AUTOSAR XML (schema 4-0-3)
standard types defined: Boolean, UInt32
package /AUTOSAR_Platform/DataConstrs
  range DC_Boolean: raw 0..1
package /PATAC/Facility/DataTypes/Implementation
  compu method COMPU_Boolean: 0=FALSE, 1=TRUE
  unit NoUnit: factor-si-to-unit=1, offset-si-to-unit=0
package /PATAC/MSM/ComponentTypes
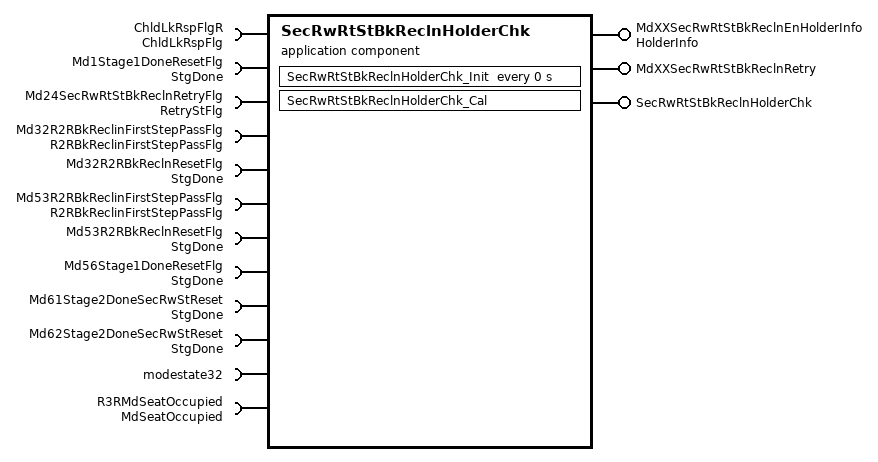
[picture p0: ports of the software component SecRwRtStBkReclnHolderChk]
  application sw component type SecRwRtStBkReclnHolderChk
    provide port MdXXSecRwRtStBkReclnEnHolderInfo: nonqueued-sender-com-spec{data-element=HolderInfo/Val, init-value=0}, provided-interface=HolderInfo
    provide port MdXXSecRwRtStBkReclnRetry: nonqueued-sender-com-spec{data-element=MdXXSecRwRtStBkReclnRetry/Val, init-value=0}, provided-interface=MdXXSecRwRtStBkReclnRetry
    provide port SecRwRtStBkReclnHolderChk: server-com-spec{operation=Cal, queue-length=1}, provided-interface=SecRwRtStBkReclnHolderChk
    12 x require port:
      ChldLkRspFlgR: nonqueued-receiver-com-spec{data-element=ChldLkRspFlg/Val, filter=data-filter-type=ALWAYS, init-value=0}, required-interface=ChldLkRspFlg
      Md1Stage1DoneResetFlg: nonqueued-receiver-com-spec{data-element=StgDone/Val, filter=data-filter-type=ALWAYS, init-value=0}, required-interface=StgDone
      Md24SecRwRtStBkReclnRetryFlg: nonqueued-receiver-com-spec{data-element=RetryStFlg/Val, filter=data-filter-type=ALWAYS, init-value=0}, required-interface=RetryStFlg
      Md32R2RBkReclinFirstStepPassFlg: nonqueued-receiver-com-spec{data-element=R2RBkReclinFirstStepPassFlg/Val, filter=data-filter-type=ALWAYS, init-value=0}, required-interface=R2RBkReclinFirstStepPassFlg
      Md32R2RBkReclnResetFlg: nonqueued-receiver-com-spec{data-element=StgDone/Val, filter=data-filter-type=ALWAYS, init-value=0}, required-interface=StgDone
      Md53R2RBkReclinFirstStepPassFlg: nonqueued-receiver-com-spec{data-element=R2RBkReclinFirstStepPassFlg/Val, filter=data-filter-type=ALWAYS, init-value=0}, required-interface=R2RBkReclinFirstStepPassFlg
      Md53R2RBkReclnResetFlg: nonqueued-receiver-com-spec{data-element=StgDone/Val, filter=data-filter-type=ALWAYS, init-value=0}, required-interface=StgDone
      Md56Stage1DoneResetFlg: nonqueued-receiver-com-spec{data-element=StgDone/Val, filter=data-filter-type=ALWAYS, init-value=0}, required-interface=StgDone
      Md61Stage2DoneSecRwStReset: nonqueued-receiver-com-spec{data-element=StgDone/Val, filter=data-filter-type=ALWAYS, init-value=0}, required-interface=StgDone
      Md62Stage2DoneSecRwStReset: nonqueued-receiver-com-spec{data-element=StgDone/Val, filter=data-filter-type=ALWAYS, init-value=0}, required-interface=StgDone
      modestate32: nonqueued-receiver-com-spec{data-element=modestate32/Val, filter=data-filter-type=ALWAYS, init-value=0}, required-interface=modestate32
      R3RMdSeatOccupied: nonqueued-receiver-com-spec{data-element=MdSeatOccupied/Val, filter=data-filter-type=ALWAYS, init-value=0}, required-interface=MdSeatOccupied
    behavior SecRwRtStBkReclnHolderChk_InternalBehavior
      operation invoked event OIT_SecRwRtStBkReclnHolderChk_Cal_SecRwRtStBkReclnHolderChk_Cal: start-on-event=SecRwRtStBkReclnHolderChk_Cal, operation=SecRwRtStBkReclnHolderChk.Cal
      timing event SecRwRtStBkReclnHolderChk_InitEvent: start-on-event=SecRwRtStBkReclnHolderChk_Init, period=0
      runnable SecRwRtStBkReclnHolderChk_Cal
        data-receive-point-by-arguments:
          12 x access:
            REC_ChldLkRspFlgR_Val: accessed-variable=ChldLkRspFlgR.Val
            REC_Md1Stage1DoneResetFlg_Val: accessed-variable=Md1Stage1DoneResetFlg.Val
            REC_Md24SecRwRtStBkReclnRetryFlg_Val: accessed-variable=Md24SecRwRtStBkReclnRetryFlg.Val
            REC_Md32R2RBkReclinFirstStepPassFlg_Val: accessed-variable=Md32R2RBkReclinFirstStepPassFlg.Val
            REC_Md32R2RBkReclnResetFlg_Val: accessed-variable=Md32R2RBkReclnResetFlg.Val
            REC_Md53R2RBkReclinFirstStepPassFlg_Val: accessed-variable=Md53R2RBkReclinFirstStepPassFlg.Val
            REC_Md53R2RBkReclnResetFlg_Val: accessed-variable=Md53R2RBkReclnResetFlg.Val
            REC_Md56Stage1DoneResetFlg_Val: accessed-variable=Md56Stage1DoneResetFlg.Val
            REC_Md61Stage2DoneSecRwStReset_Val: accessed-variable=Md61Stage2DoneSecRwStReset.Val
            REC_Md62Stage2DoneSecRwStReset_Val: accessed-variable=Md62Stage2DoneSecRwStReset.Val
            REC_modestate32_Val: accessed-variable=modestate32.Val
            REC_R3RMdSeatOccupied_Val: accessed-variable=R3RMdSeatOccupied.Val
        data-send-points:
          access SEND_MdXXSecRwRtStBkReclnEnHolderInfo_Val: accessed-variable=MdXXSecRwRtStBkReclnEnHolderInfo.Val
          access SEND_MdXXSecRwRtStBkReclnRetry_Val: accessed-variable=MdXXSecRwRtStBkReclnRetry.Val
      runnable SecRwRtStBkReclnHolderChk_Init
  swc implementation SecRwRtStBkReclnHolderChk_Implementation: behavior=SecRwRtStBkReclnHolderChk_InternalBehavior
    code-descriptors:
      code Default: artifact-descriptors=autosar-engineering-object={short-label=Default, category=SWSRC}
package /PATAC/MSM/ModeAdjust/PortInterface
  client server interface SecRwRtStBkReclnHolderChk
    operation Cal
  8 x sender receiver interface:
    ChldLkRspFlg: invalidation-policy{data-element=ChldLkRspFlg/Val, handle-invalid=DONT-INVALIDATE}
      data Val: type=Boolean
    HolderInfo: invalidation-policy{data-element=HolderInfo/Val, handle-invalid=DONT-INVALIDATE}
      data Val: type=UInt32
    MdSeatOccupied: invalidation-policy{data-element=MdSeatOccupied/Val, handle-invalid=DONT-INVALIDATE}
      data Val: type=Boolean
    MdXXSecRwRtStBkReclnRetry: invalidation-policy{data-element=MdXXSecRwRtStBkReclnRetry/Val, handle-invalid=DONT-INVALIDATE}
      data Val: type=UInt32
    modestate32: invalidation-policy{data-element=modestate32/Val, handle-invalid=DONT-INVALIDATE}
      data Val: type=UInt32
    R2RBkReclinFirstStepPassFlg: invalidation-policy{data-element=R2RBkReclinFirstStepPassFlg/Val, handle-invalid=DONT-INVALIDATE}
      data Val: type=Boolean
    RetryStFlg: invalidation-policy{data-element=RetryStFlg/Val, handle-invalid=DONT-INVALIDATE}
      data Val: type=Boolean
    StgDone: invalidation-policy{data-element=StgDone/Val, handle-invalid=DONT-INVALIDATE}
      data Val: type=Boolean
